AUTOSAR XML (schema 4-0-3)
standard types defined: Boolean, UInt32
package /AUTOSAR_Platform/DataConstrs
  range DC_Boolean: raw 0..1
package /PATAC/MSM/ComponentTypes
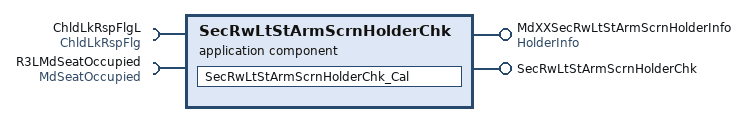
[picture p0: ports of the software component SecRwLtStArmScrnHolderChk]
  application sw component type SecRwLtStArmScrnHolderChk
    provide port MdXXSecRwLtStArmScrnHolderInfo: nonqueued-sender-com-spec{data-element=HolderInfo/Val, init-value=0}, provided-interface=HolderInfo
    provide port SecRwLtStArmScrnHolderChk: server-com-spec{operation=Cal, queue-length=1}, provided-interface=SecRwLtStArmScrnHolderChk
    require port ChldLkRspFlgL: nonqueued-receiver-com-spec{data-element=ChldLkRspFlg/Val, filter=data-filter-type=ALWAYS, init-value=0}, required-interface=ChldLkRspFlg
    require port R3LMdSeatOccupied: nonqueued-receiver-com-spec{data-element=MdSeatOccupied/Val, filter=data-filter-type=ALWAYS, init-value=0}, required-interface=MdSeatOccupied
    behavior SecRwLtStArmScrnHolderChk_InternalBehavior
      operation invoked event OIT_SecRwLtStArmScrnHolderChk_Cal_SecRwLtStArmScrnHolderChk_Cal: start-on-event=SecRwLtStArmScrnHolderChk_Cal, operation=SecRwLtStArmScrnHolderChk.Cal
      runnable SecRwLtStArmScrnHolderChk_Cal
        data-receive-point-by-arguments:
          access REC_ChldLkRspFlgL_Val: accessed-variable=ChldLkRspFlgL.Val
          access REC_R3LMdSeatOccupied_Val: accessed-variable=R3LMdSeatOccupied.Val
        data-send-points:
          access SEND_MdXXSecRwLtStArmScrnHolderInfo_Val: accessed-variable=MdXXSecRwLtStArmScrnHolderInfo.Val
  swc implementation SecRwLtStArmScrnHolderChk_Implementation: behavior=SecRwLtStArmScrnHolderChk_InternalBehavior
    code-descriptors:
      code Default: artifact-descriptors=autosar-engineering-object={short-label=Default, category=SWSRC}
package /PATAC/MSM/ModeAdjust/PortInterface
  client server interface SecRwLtStArmScrnHolderChk
    operation Cal
  sender receiver interface ChldLkRspFlg: invalidation-policy{data-element=ChldLkRspFlg/Val, handle-invalid=DONT-INVALIDATE}
    data Val: type=Boolean
  sender receiver interface HolderInfo: invalidation-policy{data-element=HolderInfo/Val, handle-invalid=DONT-INVALIDATE}
    data Val: type=UInt32
  sender receiver interface MdSeatOccupied: invalidation-policy{data-element=MdSeatOccupied/Val, handle-invalid=DONT-INVALIDATE}
    data Val: type=Boolean
